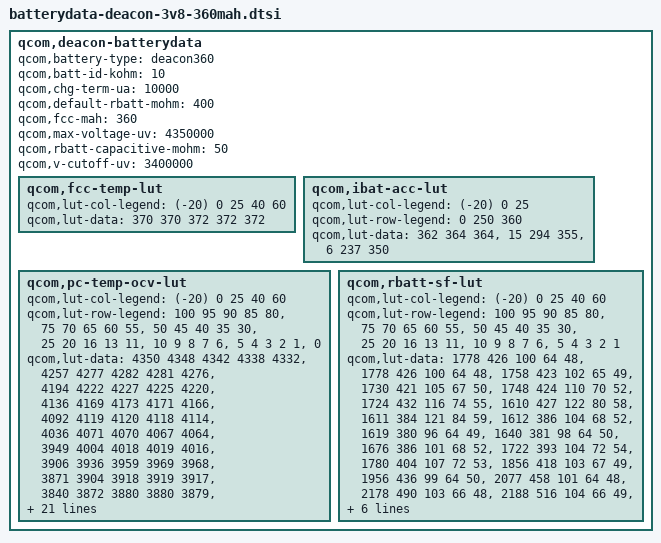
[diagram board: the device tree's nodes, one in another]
/* Copyright (c) 2015, The Linux Foundation. All rights reserved.
 *
 * This program is free software; you can redistribute it and/or modify
 * it under the terms of the GNU General Public License version 2 and
 * only version 2 as published by the Free Software Foundation.
 *
 * This program is distributed in the hope that it will be useful,
 * but WITHOUT ANY WARRANTY; without even the implied warranty of
 * MERCHANTABILITY or FITNESS FOR A PARTICULAR PURPOSE.  See the
 * GNU General Public License for more details.
 */


qcom,deacon-batterydata {
	qcom,battery-type = "deacon360";
	qcom,batt-id-kohm = <10>;
	qcom,chg-term-ua = <10000>;
	qcom,default-rbatt-mohm = <400>;
	qcom,fcc-mah = <360>;
	qcom,max-voltage-uv = <4350000>;
	qcom,rbatt-capacitive-mohm = <50>;
	qcom,v-cutoff-uv = <3400000>;
	qcom,fcc-temp-lut {
		qcom,lut-col-legend = <(-20) 0 25 40 60>;
		qcom,lut-data = <370 370 372 372 372>;
	};

	qcom,ibat-acc-lut {
		qcom,lut-col-legend = <(-20) 0 25>;
		qcom,lut-row-legend = <0 250 360>;
		qcom,lut-data = <362 364 364>,
				<15 294 355>,
				<6 237 350>;
	};

	qcom,pc-temp-ocv-lut {
		qcom,lut-col-legend = <(-20) 0 25 40 60>;
		qcom,lut-row-legend = <100 95 90 85 80>,
					<75 70 65 60 55>,
					<50 45 40 35 30>,
					<25 20 16 13 11>,
					<10 9 8 7 6>,
					<5 4 3 2 1>,
					<0>;
		qcom,lut-data = <4350 4348 4342 4338 4332>,
				<4257 4277 4282 4281 4276>,
				<4194 4222 4227 4225 4220>,
				<4136 4169 4173 4171 4166>,
				<4092 4119 4120 4118 4114>,
				<4036 4071 4070 4067 4064>,
				<3949 4004 4018 4019 4016>,
				<3906 3936 3959 3969 3968>,
				<3871 3904 3918 3919 3917>,
				<3840 3872 3880 3880 3879>,
				<3817 3843 3851 3851 3850>,
				<3798 3818 3827 3827 3826>,
				<3784 3798 3806 3806 3804>,
				<3770 3782 3788 3786 3780>,
				<3754 3767 3767 3761 3750>,
				<3739 3751 3746 3738 3726>,
				<3720 3732 3725 3716 3702>,
				<3700 3716 3702 3694 3678>,
				<3682 3704 3692 3684 3671>,
				<3668 3698 3688 3680 3668>,
				<3659 3695 3686 3678 3666>,
				<3648 3690 3684 3674 3660>,
				<3634 3683 3674 3663 3643>,
				<3617 3668 3649 3638 3614>,
				<3594 3640 3614 3604 3579>,
				<3565 3602 3573 3564 3538>,
				<3524 3552 3526 3516 3488>,
				<3464 3488 3463 3456 3424>,
				<3372 3406 3380 3373 3330>,
				<3250 3292 3242 3236 3194>,
				<3000 3010 3000 3000 3000>;
	};

	qcom,rbatt-sf-lut {
		qcom,lut-col-legend = <(-20) 0 25 40 60>;
		qcom,lut-row-legend = <100 95 90 85 80>,
					<75 70 65 60 55>,
					<50 45 40 35 30>,
					<25 20 16 13 11>,
					<10 9 8 7 6>,
					<5 4 3 2 1>;
		qcom,lut-data = <1778 426 100 64 48>,
				<1778 426 100 64 48>,
				<1758 423 102 65 49>,
				<1730 421 105 67 50>,
				<1748 424 110 70 52>,
				<1724 432 116 74 55>,
				<1610 427 122 80 58>,
				<1611 384 121 84 59>,
				<1612 386 104 68 52>,
				<1619 380 96 64 49>,
				<1640 381 98 64 50>,
				<1676 386 101 68 52>,
				<1722 393 104 72 54>,
				<1780 404 107 72 53>,
				<1856 418 103 67 49>,
				<1956 436 99 64 50>,
				<2077 458 101 64 48>,
				<2178 490 103 66 48>,
				<2188 516 104 66 49>,
				<2197 540 110 69 50>,
				<2250 557 114 70 52>,
				<2303 579 118 72 52>,
				<2363 600 119 72 54>,
				<2432 608 118 75 60>,
				<2509 620 124 82 68>,
				<2728 642 140 94 75>,
				<3146 678 152 104 87>,
				<3828 728 178 121 100>,
				<5105 815 216 151 131>,
				<10210 1024 432 302 262>;
	};

};
